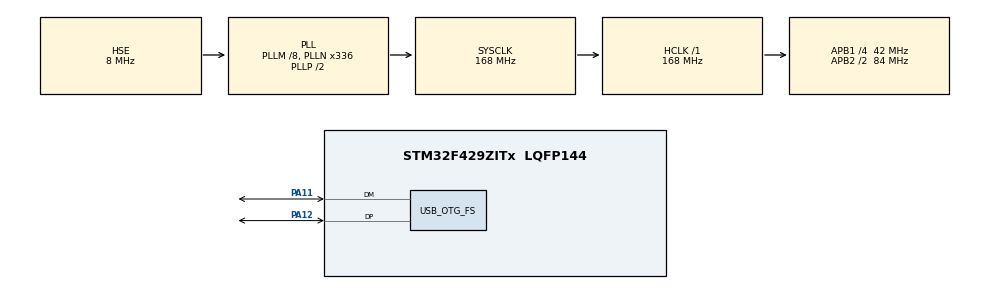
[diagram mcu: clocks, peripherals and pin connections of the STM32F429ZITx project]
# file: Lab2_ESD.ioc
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FREERTOS.Tasks01=GyroSample,24,1024,StartGyroSample,Default,NULL,Dynamic,NULL,NULL;DisplayLCD,23,1024,StartDisplayLCD,Default,NULL,Dynamic,NULL,NULL
FREERTOS.configUSE_NEWLIB_REENTRANT=1
Mcu.Family=STM32F4
Mcu.Name=STM32F429ZITx
Mcu.Package=LQFP144
NVIC.OTG_FS_IRQn=true\:5\:0\:false\:false\:true\:true\:false\:true\:true
NVIC.PriorityGroup=NVIC_PRIORITYGROUP_4
NVIC.TIM6_DAC_IRQn=true\:15\:0\:false\:false\:true\:false\:false\:true\:true
NVIC.TimeBase=TIM6_DAC_IRQn
NVIC.TimeBaseIP=TIM6
PA11.Mode=Device_Only
PA11.Signal=USB_OTG_FS_DM
PA12.Mode=Device_Only
PA12.Signal=USB_OTG_FS_DP
PA13.Mode=Serial_Wire
PA13.Signal=SYS_JTMS-SWDIO
PA14.Mode=Serial_Wire
PA14.Signal=SYS_JTCK-SWCLK
PH0/OSC_IN.Mode=HSE-External-Oscillator
PH0/OSC_IN.Signal=RCC_OSC_IN
PH1/OSC_OUT.Mode=HSE-External-Oscillator
PH1/OSC_OUT.Signal=RCC_OSC_OUT
ProjectManager.HeapSize=0x200
ProjectManager.StackSize=0x400
ProjectManager.TargetToolchain=STM32CubeIDE
RCC.48MHZClocksFreq_Value=48000000
RCC.AHBFreq_Value=168000000
RCC.APB1CLKDivider=RCC_HCLK_DIV4
RCC.APB1Freq_Value=42000000
RCC.APB1TimFreq_Value=84000000
RCC.APB2CLKDivider=RCC_HCLK_DIV2
RCC.APB2Freq_Value=84000000
RCC.APB2TimFreq_Value=168000000
RCC.CortexFreq_Value=168000000
RCC.HCLKFreq_Value=168000000
RCC.HSE_VALUE=8000000
RCC.HSI_VALUE=16000000
RCC.LSE_VALUE=32768
RCC.PLLM=8
RCC.PLLN=336
RCC.PLLQ=7
RCC.SYSCLKFreq_VALUE=168000000
RCC.SYSCLKSource=RCC_SYSCLKSOURCE_PLLCLK
RCC.VCOOutputFreq_Value=336000000
USB_DEVICE.CLASS_NAME_FS=CDC
USB_DEVICE.VirtualMode-CDC_FS=Cdc
USB_DEVICE.VirtualModeFS=Cdc_FS
USB_OTG_FS.VirtualMode=Device_Only
VP_FREERTOS_VS_CMSIS_V2.Mode=CMSIS_V2
VP_SYS_VS_tim6.Mode=TIM6
VP_USB_DEVICE_VS_USB_DEVICE_CDC_FS.Mode=CDC_FS
board=custom

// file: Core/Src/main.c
/* USER CODE BEGIN Header */
/**
  ******************************************************************************
  * @file           : main.c
  * @brief          : Main program body
  ******************************************************************************
  * @attention
  *
  * Copyright (c) 2023 STMicroelectronics.
  * All rights reserved.
  *
  * This software is licensed under terms that can be found in the LICENSE file
  * in the root directory of this software component.
  * If no LICENSE file comes with this software, it is provided AS-IS.
  *
  ******************************************************************************
  */
/* USER CODE END Header */
#include "main.h"
#include "cmsis_os.h"
#include "usb_device.h"

/* USER CODE BEGIN Includes */
#include "stm32f429i_discovery_lcd.h"
#include "stm32f429i_discovery_gyroscope.h"
#include "stdio.h"
#include "usbd_cdc_if.h"
/* USER CODE END Includes */

/* USER CODE BEGIN PD */
#define SAMPLE_PERIOD_MS 10 // ms
#define LCD_WIDTH 240
#define LCD_HEIGHT 320
#define TRIANGLE_LENGTH 50
#define TRIANGLE_HEIGHT 43 // ~~ 20sin(60)

/* USER CODE END PD */

/* Definitions for GyroSample */
osThreadId_t GyroSampleHandle;
const osThreadAttr_t GyroSample_attributes = {
  .name = "GyroSample",
  .stack_size = 1024 * 4,
  .priority = (osPriority_t) osPriorityNormal,
};
/* Definitions for DisplayLCD */
osThreadId_t DisplayLCDHandle;
const osThreadAttr_t DisplayLCD_attributes = {
  .name = "DisplayLCD",
  .stack_size = 1024 * 4,
  .priority = (osPriority_t) osPriorityBelowNormal7,
};
/* USER CODE BEGIN PV */
float xAngle = 0, yAngle = 0, zAngle = 0;
float rawData[3];
/* USER CODE END PV */

void SystemClock_Config(void);
static void MX_GPIO_Init(void);
void StartGyroSample(void *argument);
void StartDisplayLCD(void *argument);

int main(void)
{

  /* MCU Configuration--------------------------------------------------------*/

  /* Reset of all peripherals, Initializes the Flash interface and the Systick. */
  HAL_Init();

  /* Configure the system clock */
  SystemClock_Config();

  /* Initialize all configured peripherals */
  MX_GPIO_Init();
  /* USER CODE BEGIN 2 */
  MX_USB_DEVICE_Init();
  BSP_GYRO_Init(); // L3GD20_FULLSCALE_500
  BSP_LCD_Init();
  BSP_LCD_LayerDefaultInit(1, SDRAM_DEVICE_ADDR);
  BSP_LCD_SelectLayer(1);//select on which layer we write
  BSP_LCD_DisplayOn();//turn on LCD
  BSP_LCD_Clear(LCD_COLOR_WHITE);//clear the LCD on white color
  BSP_LCD_SetBackColor(LCD_COLOR_WHITE);//set text background color
  BSP_LCD_SetTextColor(LCD_COLOR_BLUE);
  /* USER CODE END 2 */

  /* Init scheduler */
  osKernelInitialize();

  /* Create the thread(s) */
  /* creation of GyroSample */
  GyroSampleHandle = osThreadNew(StartGyroSample, NULL, &GyroSample_attributes);

  /* creation of DisplayLCD */
  DisplayLCDHandle = osThreadNew(StartDisplayLCD, NULL, &DisplayLCD_attributes);

  /* Start scheduler */
  osKernelStart();

  /* We should never get here as control is now taken by the scheduler */
  /* Infinite loop */
  while (1)
  {

  }
}

void SystemClock_Config(void)
{
  RCC_OscInitTypeDef RCC_OscInitStruct = {0};
  RCC_ClkInitTypeDef RCC_ClkInitStruct = {0};

  /** Configure the main internal regulator output voltage
  */
  __HAL_RCC_PWR_CLK_ENABLE();
  __HAL_PWR_VOLTAGESCALING_CONFIG(PWR_REGULATOR_VOLTAGE_SCALE1);

  /** Initializes the RCC Oscillators according to the specified parameters
  * in the RCC_OscInitTypeDef structure.
  */
  RCC_OscInitStruct.OscillatorType = RCC_OSCILLATORTYPE_HSE;
  RCC_OscInitStruct.HSEState = RCC_HSE_ON;
  RCC_OscInitStruct.PLL.PLLState = RCC_PLL_ON;
  RCC_OscInitStruct.PLL.PLLSource = RCC_PLLSOURCE_HSE;
  RCC_OscInitStruct.PLL.PLLM = 8;
  RCC_OscInitStruct.PLL.PLLN = 336;
  RCC_OscInitStruct.PLL.PLLP = RCC_PLLP_DIV2;
  RCC_OscInitStruct.PLL.PLLQ = 7;
  if (HAL_RCC_OscConfig(&RCC_OscInitStruct) != HAL_OK)
  {
    Error_Handler();
  }

  /** Initializes the CPU, AHB and APB buses clocks
  */
  RCC_ClkInitStruct.ClockType = RCC_CLOCKTYPE_HCLK|RCC_CLOCKTYPE_SYSCLK
                              |RCC_CLOCKTYPE_PCLK1|RCC_CLOCKTYPE_PCLK2;
  RCC_ClkInitStruct.SYSCLKSource = RCC_SYSCLKSOURCE_PLLCLK;
  RCC_ClkInitStruct.AHBCLKDivider = RCC_SYSCLK_DIV1;
  RCC_ClkInitStruct.APB1CLKDivider = RCC_HCLK_DIV4;
  RCC_ClkInitStruct.APB2CLKDivider = RCC_HCLK_DIV2;

  if (HAL_RCC_ClockConfig(&RCC_ClkInitStruct, FLASH_LATENCY_5) != HAL_OK)
  {
    Error_Handler();
  }
}

static void MX_GPIO_Init(void)
{

  /* GPIO Ports Clock Enable */
  __HAL_RCC_GPIOH_CLK_ENABLE();
  __HAL_RCC_GPIOA_CLK_ENABLE();

}

void StartGyroSample(void *argument)
{
  /* init code for USB_DEVICE */
  MX_USB_DEVICE_Init();
  /* USER CODE BEGIN 5 */
  /* Infinite loop */
  for(;;)
  {
	BSP_GYRO_GetXYZ(rawData);
	for(uint8_t i = 0; i < 3; i++) {
		// Convert Gyro raw to degrees per second, L3GD20_FULLSCALE_500
		rawData[i] = rawData[i]*0.01750;
	}
	xAngle += rawData[0] * SAMPLE_PERIOD_MS / 1000.0;
	yAngle += rawData[1] * SAMPLE_PERIOD_MS / 1000.0;
	zAngle += rawData[2] * SAMPLE_PERIOD_MS / 1000.0;

	char stringBuf[100];
	sprintf(stringBuf, "xAngle: %f\nyAngle: %f\nyAngle: %f", xAngle, yAngle, zAngle);
	CDC_Transmit_FS((uint8_t*)stringBuf, strlen(stringBuf));

	osDelay(SAMPLE_PERIOD_MS); // tan so lay mau la 100 Hz
  }
  /* USER CODE END 5 */
}

void StartDisplayLCD(void *argument)
{
  /* USER CODE BEGIN StartDisplayLCD */
  /* Infinite loop */
  for(;;)
  {
	BSP_LCD_Clear(LCD_COLOR_WHITE);
	if(xAngle >= 0) {
		// draw bottom triangle
		BSP_LCD_FillTriangle(LCD_WIDTH/2 - TRIANGLE_LENGTH/2, LCD_WIDTH/2, LCD_WIDTH/2  + TRIANGLE_LENGTH/2,
			LCD_HEIGHT - 5 - TRIANGLE_HEIGHT, LCD_HEIGHT - 5, LCD_HEIGHT - 5 - TRIANGLE_HEIGHT);
	} else {
		// draw top triangle
		BSP_LCD_FillTriangle(LCD_WIDTH/2 - TRIANGLE_LENGTH/2, LCD_WIDTH/2, LCD_WIDTH/2  + TRIANGLE_LENGTH/2,
				5 + TRIANGLE_HEIGHT, 5, 5 + TRIANGLE_HEIGHT);
	}
	if(yAngle >= 0) {
		// draw right triangle
		BSP_LCD_FillTriangle(LCD_WIDTH - 5 - TRIANGLE_HEIGHT, LCD_WIDTH - 5 - TRIANGLE_HEIGHT, LCD_WIDTH - 5,
							LCD_HEIGHT/2 - TRIANGLE_LENGTH/2, LCD_HEIGHT/2 + TRIANGLE_LENGTH/2, LCD_HEIGHT/2);
	} else {
		// draw left triangle
		BSP_LCD_FillTriangle(5, TRIANGLE_HEIGHT + 5, TRIANGLE_HEIGHT + 5,
				LCD_HEIGHT/2, LCD_HEIGHT/2 - TRIANGLE_LENGTH/2, LCD_HEIGHT/2 + TRIANGLE_LENGTH/2);
	}
	osDelay(1000/30); // 30fps
  }
  /* USER CODE END StartDisplayLCD */
}

void HAL_TIM_PeriodElapsedCallback(TIM_HandleTypeDef *htim)
{
  if (htim->Instance == TIM6) {
    HAL_IncTick();
  }
}

void Error_Handler(void)
{
  __disable_irq();
  while (1)
  {
  }
}
